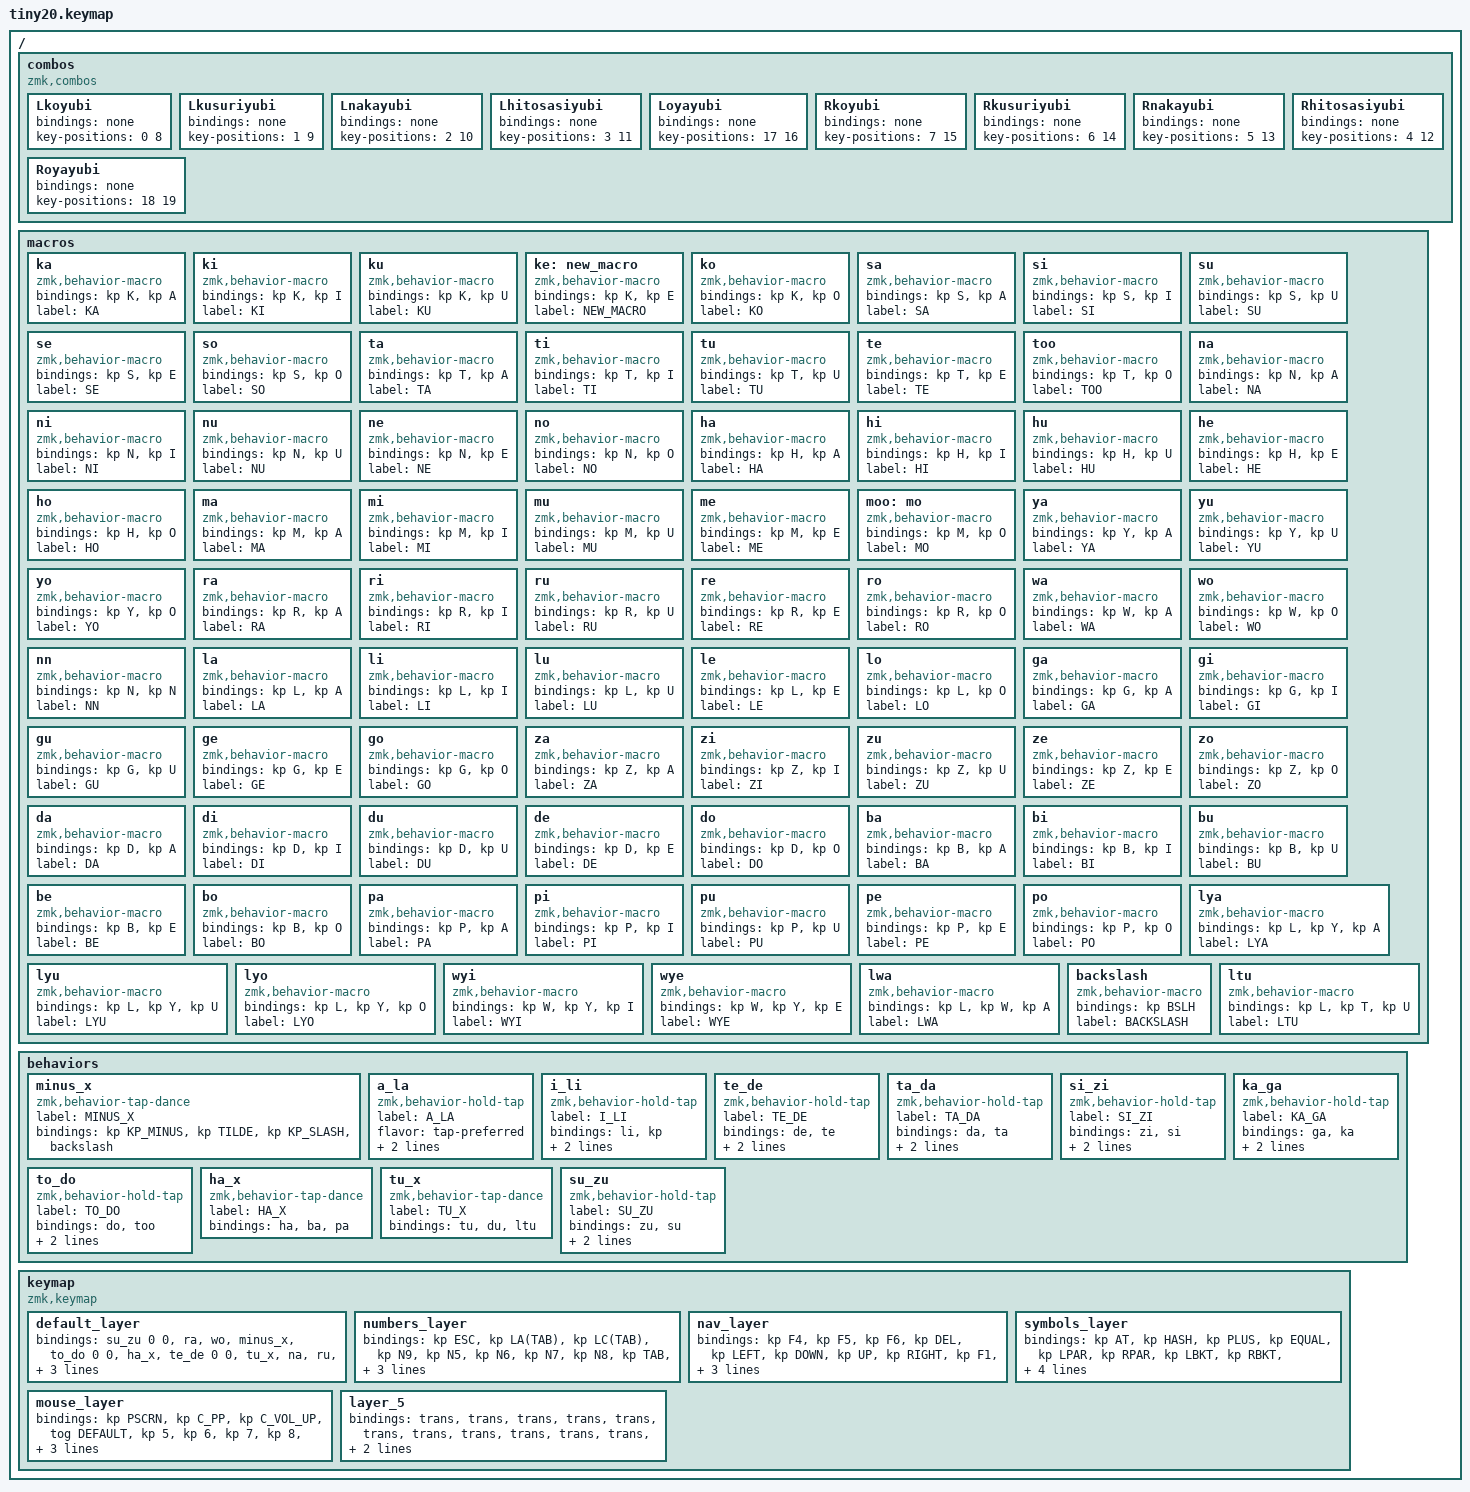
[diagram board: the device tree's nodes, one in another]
/*
 * Copyright (c) 2022 The ZMK Contributors
 *
 * SPDX-License-Identifier: MIT
 */

#include <behaviors.dtsi>
#include <dt-bindings/zmk/keys.h>

#define DEFAULT 0
#define NUMBERS 1
#define NAV 2
#define SYMBOLS 3
#define MOUSE 4

/ {
    combos {
        compatible = "zmk,combos";

        Lkoyubi {
            bindings = <&none>;
            key-positions = <0 8>;
        };

        Lkusuriyubi {
            bindings = <&none>;
            key-positions = <1 9>;
        };

        Lnakayubi {
            bindings = <&none>;
            key-positions = <2 10>;
        };

        Lhitosasiyubi {
            bindings = <&none>;
            key-positions = <3 11>;
        };

        Loyayubi {
            bindings = <&none>;
            key-positions = <17 16>;
        };

        Rkoyubi {
            bindings = <&none>;
            key-positions = <7 15>;
        };

        Rkusuriyubi {
            bindings = <&none>;
            key-positions = <6 14>;
        };

        Rnakayubi {
            bindings = <&none>;
            key-positions = <5 13>;
        };

        Rhitosasiyubi {
            bindings = <&none>;
            key-positions = <4 12>;
        };

        Royayubi {
            bindings = <&none>;
            key-positions = <18 19>;
        };
    };

    macros {
        ka: ka {
            compatible = "zmk,behavior-macro";
            #binding-cells = <0>;
            bindings = <&kp K &kp A>;
            label = "KA";
        };

        ki: ki {
            compatible = "zmk,behavior-macro";
            #binding-cells = <0>;
            bindings = <&kp K &kp I>;
            label = "KI";
        };

        ku: ku {
            compatible = "zmk,behavior-macro";
            #binding-cells = <0>;
            bindings = <&kp K &kp U>;
            label = "KU";
        };

        ke: new_macro {
            compatible = "zmk,behavior-macro";
            #binding-cells = <0>;
            bindings = <&kp K &kp E>;
            label = "NEW_MACRO";
        };

        ko: ko {
            compatible = "zmk,behavior-macro";
            #binding-cells = <0>;
            bindings = <&kp K &kp O>;
            label = "KO";
        };

        sa: sa {
            compatible = "zmk,behavior-macro";
            #binding-cells = <0>;
            bindings = <&kp S &kp A>;
            label = "SA";
        };

        si: si {
            compatible = "zmk,behavior-macro";
            #binding-cells = <0>;
            bindings = <&kp S &kp I>;
            label = "SI";
        };

        su: su {
            compatible = "zmk,behavior-macro";
            #binding-cells = <0>;
            bindings = <&kp S &kp U>;
            label = "SU";
        };

        se: se {
            compatible = "zmk,behavior-macro";
            #binding-cells = <0>;
            bindings = <&kp S &kp E>;
            label = "SE";
        };

        so: so {
            compatible = "zmk,behavior-macro";
            #binding-cells = <0>;
            bindings = <&kp S &kp O>;
            label = "SO";
        };

        ta: ta {
            compatible = "zmk,behavior-macro";
            #binding-cells = <0>;
            bindings = <&kp T &kp A>;
            label = "TA";
        };

        ti: ti {
            compatible = "zmk,behavior-macro";
            #binding-cells = <0>;
            bindings = <&kp T &kp I>;
            label = "TI";
        };

        tu: tu {
            compatible = "zmk,behavior-macro";
            #binding-cells = <0>;
            bindings = <&kp T &kp U>;
            label = "TU";
        };

        te: te {
            compatible = "zmk,behavior-macro";
            #binding-cells = <0>;
            bindings = <&kp T &kp E>;
            label = "TE";
        };

        too: too {
            compatible = "zmk,behavior-macro";
            #binding-cells = <0>;
            bindings = <&kp T &kp O>;
            label = "TOO";
        };

        na: na {
            compatible = "zmk,behavior-macro";
            #binding-cells = <0>;
            bindings = <&kp N &kp A>;
            label = "NA";
        };

        ni: ni {
            compatible = "zmk,behavior-macro";
            #binding-cells = <0>;
            bindings = <&kp N &kp I>;
            label = "NI";
        };

        nu: nu {
            compatible = "zmk,behavior-macro";
            #binding-cells = <0>;
            bindings = <&kp N &kp U>;
            label = "NU";
        };

        ne: ne {
            compatible = "zmk,behavior-macro";
            #binding-cells = <0>;
            bindings = <&kp N &kp E>;
            label = "NE";
        };

        no: no {
            compatible = "zmk,behavior-macro";
            #binding-cells = <0>;
            bindings = <&kp N &kp O>;
            label = "NO";
        };

        ha: ha {
            compatible = "zmk,behavior-macro";
            #binding-cells = <0>;
            bindings = <&kp H &kp A>;
            label = "HA";
        };

        hi: hi {
            compatible = "zmk,behavior-macro";
            #binding-cells = <0>;
            bindings = <&kp H &kp I>;
            label = "HI";
        };

        hu: hu {
            compatible = "zmk,behavior-macro";
            #binding-cells = <0>;
            bindings = <&kp H &kp U>;
            label = "HU";
        };

        he: he {
            compatible = "zmk,behavior-macro";
            #binding-cells = <0>;
            bindings = <&kp H &kp E>;
            label = "HE";
        };

        ho: ho {
            compatible = "zmk,behavior-macro";
            #binding-cells = <0>;
            bindings = <&kp H &kp O>;
            label = "HO";
        };

        ma: ma {
            compatible = "zmk,behavior-macro";
            #binding-cells = <0>;
            bindings = <&kp M &kp A>;
            label = "MA";
        };

        mi: mi {
            compatible = "zmk,behavior-macro";
            #binding-cells = <0>;
            bindings = <&kp M &kp I>;
            label = "MI";
        };

        mu: mu {
            compatible = "zmk,behavior-macro";
            #binding-cells = <0>;
            bindings = <&kp M &kp U>;
            label = "MU";
        };

        me: me {
            compatible = "zmk,behavior-macro";
            #binding-cells = <0>;
            bindings = <&kp M &kp E>;
            label = "ME";
        };

        moo: mo {
            compatible = "zmk,behavior-macro";
            #binding-cells = <0>;
            bindings = <&kp M &kp O>;
            label = "MO";
        };

        ya: ya {
            compatible = "zmk,behavior-macro";
            #binding-cells = <0>;
            bindings = <&kp Y &kp A>;
            label = "YA";
        };

        yu: yu {
            compatible = "zmk,behavior-macro";
            #binding-cells = <0>;
            bindings = <&kp Y &kp U>;
            label = "YU";
        };

        yo: yo {
            compatible = "zmk,behavior-macro";
            #binding-cells = <0>;
            bindings = <&kp Y &kp O>;
            label = "YO";
        };

        ra: ra {
            compatible = "zmk,behavior-macro";
            #binding-cells = <0>;
            bindings = <&kp R &kp A>;
            label = "RA";
        };

        ri: ri {
            compatible = "zmk,behavior-macro";
            #binding-cells = <0>;
            bindings = <&kp R &kp I>;
            label = "RI";
        };

        ru: ru {
            compatible = "zmk,behavior-macro";
            #binding-cells = <0>;
            bindings = <&kp R &kp U>;
            label = "RU";
        };

        re: re {
            compatible = "zmk,behavior-macro";
            #binding-cells = <0>;
            bindings = <&kp R &kp E>;
            label = "RE";
        };

        ro: ro {
            compatible = "zmk,behavior-macro";
            #binding-cells = <0>;
            bindings = <&kp R &kp O>;
            label = "RO";
        };

        wa: wa {
            compatible = "zmk,behavior-macro";
            #binding-cells = <0>;
            bindings = <&kp W &kp A>;
            label = "WA";
        };

        wo: wo {
            compatible = "zmk,behavior-macro";
            #binding-cells = <0>;
            bindings = <&kp W &kp O>;
            label = "WO";
        };

        nn: nn {
            compatible = "zmk,behavior-macro";
            #binding-cells = <0>;
            bindings = <&kp N &kp N>;
            label = "NN";
        };

        la: la {
            compatible = "zmk,behavior-macro";
            #binding-cells = <0>;
            bindings = <&kp L &kp A>;
            label = "LA";
        };

        li: li {
            compatible = "zmk,behavior-macro";
            #binding-cells = <0>;
            bindings = <&kp L &kp I>;
            label = "LI";
        };

        lu: lu {
            compatible = "zmk,behavior-macro";
            #binding-cells = <0>;
            bindings = <&kp L &kp U>;
            label = "LU";
        };

        le: le {
            compatible = "zmk,behavior-macro";
            #binding-cells = <0>;
            bindings = <&kp L &kp E>;
            label = "LE";
        };

        lo: lo {
            compatible = "zmk,behavior-macro";
            #binding-cells = <0>;
            bindings = <&kp L &kp O>;
            label = "LO";
        };

        ga: ga {
            compatible = "zmk,behavior-macro";
            #binding-cells = <0>;
            bindings = <&kp G &kp A>;
            label = "GA";
        };

        gi: gi {
            compatible = "zmk,behavior-macro";
            #binding-cells = <0>;
            bindings = <&kp G &kp I>;
            label = "GI";
        };

        gu: gu {
            compatible = "zmk,behavior-macro";
            #binding-cells = <0>;
            bindings = <&kp G &kp U>;
            label = "GU";
        };

        ge: ge {
            compatible = "zmk,behavior-macro";
            #binding-cells = <0>;
            bindings = <&kp G &kp E>;
            label = "GE";
        };

        go: go {
            compatible = "zmk,behavior-macro";
            #binding-cells = <0>;
            bindings = <&kp G &kp O>;
            label = "GO";
        };

        za: za {
            compatible = "zmk,behavior-macro";
            #binding-cells = <0>;
            bindings = <&kp Z &kp A>;
            label = "ZA";
        };

        zi: zi {
            compatible = "zmk,behavior-macro";
            #binding-cells = <0>;
            bindings = <&kp Z &kp I>;
            label = "ZI";
        };

        zu: zu {
            compatible = "zmk,behavior-macro";
            #binding-cells = <0>;
            bindings = <&kp Z &kp U>;
            label = "ZU";
        };

        ze: ze {
            compatible = "zmk,behavior-macro";
            #binding-cells = <0>;
            bindings = <&kp Z &kp E>;
            label = "ZE";
        };

        zo: zo {
            compatible = "zmk,behavior-macro";
            #binding-cells = <0>;
            bindings = <&kp Z &kp O>;
            label = "ZO";
        };

        da: da {
            compatible = "zmk,behavior-macro";
            #binding-cells = <0>;
            bindings = <&kp D &kp A>;
            label = "DA";
        };

        di: di {
            compatible = "zmk,behavior-macro";
            #binding-cells = <0>;
            bindings = <&kp D &kp I>;
            label = "DI";
        };

        du: du {
            compatible = "zmk,behavior-macro";
            #binding-cells = <0>;
            bindings = <&kp D &kp U>;
            label = "DU";
        };

        de: de {
            compatible = "zmk,behavior-macro";
            #binding-cells = <0>;
            bindings = <&kp D &kp E>;
            label = "DE";
        };

        do: do {
            compatible = "zmk,behavior-macro";
            #binding-cells = <0>;
            bindings = <&kp D &kp O>;
            label = "DO";
        };

        ba: ba {
            compatible = "zmk,behavior-macro";
            #binding-cells = <0>;
            bindings = <&kp B &kp A>;
            label = "BA";
        };

        bi: bi {
            compatible = "zmk,behavior-macro";
            #binding-cells = <0>;
            bindings = <&kp B &kp I>;
            label = "BI";
        };

        bu: bu {
            compatible = "zmk,behavior-macro";
            #binding-cells = <0>;
            bindings = <&kp B &kp U>;
            label = "BU";
        };

        be: be {
            compatible = "zmk,behavior-macro";
            #binding-cells = <0>;
            bindings = <&kp B &kp E>;
            label = "BE";
        };

        bo: bo {
            compatible = "zmk,behavior-macro";
            #binding-cells = <0>;
            bindings = <&kp B &kp O>;
            label = "BO";
        };

        pa: pa {
            compatible = "zmk,behavior-macro";
            #binding-cells = <0>;
            bindings = <&kp P &kp A>;
            label = "PA";
        };

        pi: pi {
            compatible = "zmk,behavior-macro";
            #binding-cells = <0>;
            bindings = <&kp P &kp I>;
            label = "PI";
        };

        pu: pu {
            compatible = "zmk,behavior-macro";
            #binding-cells = <0>;
            bindings = <&kp P &kp U>;
            label = "PU";
        };

        pe: pe {
            compatible = "zmk,behavior-macro";
            #binding-cells = <0>;
            bindings = <&kp P &kp E>;
            label = "PE";
        };

        po: po {
            compatible = "zmk,behavior-macro";
            #binding-cells = <0>;
            bindings = <&kp P &kp O>;
            label = "PO";
        };

        lya: lya {
            compatible = "zmk,behavior-macro";
            #binding-cells = <0>;
            bindings = <&kp L &kp Y &kp A>;
            label = "LYA";
        };

        lyu: lyu {
            compatible = "zmk,behavior-macro";
            #binding-cells = <0>;
            bindings = <&kp L &kp Y &kp U>;
            label = "LYU";
        };

        lyo: lyo {
            compatible = "zmk,behavior-macro";
            #binding-cells = <0>;
            bindings = <&kp L &kp Y &kp O>;
            label = "LYO";
        };

        wyi: wyi {
            compatible = "zmk,behavior-macro";
            #binding-cells = <0>;
            bindings = <&kp W &kp Y &kp I>;
            label = "WYI";
        };

        wye: wye {
            compatible = "zmk,behavior-macro";
            #binding-cells = <0>;
            bindings = <&kp W &kp Y &kp E>;
            label = "WYE";
        };

        lwa: lwa {
            compatible = "zmk,behavior-macro";
            #binding-cells = <0>;
            bindings = <&kp L &kp W &kp A>;
            label = "LWA";
        };

        backslash: backslash {
            compatible = "zmk,behavior-macro";
            #binding-cells = <0>;
            bindings = <&kp BSLH>;
            label = "BACKSLASH";
        };

        ltu: ltu {
            compatible = "zmk,behavior-macro";
            #binding-cells = <0>;
            bindings = <&kp L &kp T &kp U>;
            label = "LTU";
        };
    };

    behaviors {
        minus_x: minus_x {
            compatible = "zmk,behavior-tap-dance";
            label = "MINUS_X";
            #binding-cells = <0>;
            bindings =
                <&kp KP_MINUS>,
                <&kp TILDE>,
                <&kp KP_SLASH>,
                <&backslash>;
        };

        a_la: a_la {
            compatible = "zmk,behavior-hold-tap";
            label = "A_LA";
            #binding-cells = <2>;
            flavor = "tap-preferred";
            tapping-term-ms = <1>;
            bindings = <&la>, <&kp>;
        };

        i_li: i_li {
            compatible = "zmk,behavior-hold-tap";
            label = "I_LI";
            bindings = <&li>, <&kp>;

            #binding-cells = <2>;
            tapping-term-ms = <1>;
            flavor = "tap-preferred";
        };

        te_de: te_de {
            compatible = "zmk,behavior-hold-tap";
            label = "TE_DE";
            bindings = <&de>, <&te>;

            #binding-cells = <2>;
            tapping-term-ms = <1>;
            flavor = "tap-preferred";
        };

        ta_da: ta_da {
            compatible = "zmk,behavior-hold-tap";
            label = "TA_DA";
            bindings = <&da>, <&ta>;

            #binding-cells = <2>;
            tapping-term-ms = <1>;
            flavor = "tap-preferred";
        };

        si_zi: si_zi {
            compatible = "zmk,behavior-hold-tap";
            label = "SI_ZI";
            bindings = <&zi>, <&si>;

            #binding-cells = <2>;
            flavor = "tap-preferred";
            tapping-term-ms = <1>;
        };

        ka_ga: ka_ga {
            compatible = "zmk,behavior-hold-tap";
            label = "KA_GA";
            bindings = <&ga>, <&ka>;

            #binding-cells = <2>;
            tapping-term-ms = <1>;
            flavor = "tap-preferred";
        };

        to_do: to_do {
            compatible = "zmk,behavior-hold-tap";
            label = "TO_DO";
            bindings = <&do>, <&too>;

            #binding-cells = <2>;
            tapping-term-ms = <1>;
            flavor = "tap-preferred";
        };

        ha_x: ha_x {
            compatible = "zmk,behavior-tap-dance";
            label = "HA_X";
            #binding-cells = <0>;
            bindings = <&ha>, <&ba>, <&pa>;
        };

        tu_x: tu_x {
            compatible = "zmk,behavior-tap-dance";
            label = "TU_X";
            #binding-cells = <0>;
            bindings = <&tu>, <&du>, <&ltu>;
        };

        su_zu: su_zu {
            compatible = "zmk,behavior-hold-tap";
            label = "SU_ZU";
            bindings = <&zu>, <&su>;

            #binding-cells = <2>;
            flavor = "tap-preferred";
            tapping-term-ms = <1>;
        };
    };

    keymap {
        compatible = "zmk,keymap";

        // This is a sample keymap intended to be replaced with your own

        default_layer {
            bindings = <
&su_zu 0 0  &ra  &wo  &minus_x  &to_do 0 0  &ha_x  &te_de 0 0  &tu_x  &na  &ru  &ni  &no  &i_li 0 I  &ta_da 0 0  &si_zi 0 0  &ka_ga 0 0  &tog 5  &lt NUMBERS ENTER  &lt NAV SPACE  &kp KP_COMMA
            >;
        };

        numbers_layer {
            bindings = <
&kp ESC  &kp LA(TAB)  &kp LC(TAB)  &kp N9  &kp N5  &kp N6  &kp N7  &kp N8  &kp TAB  &kp LA(F4)  &kp LC(F4)  &kp N0  &kp N1  &kp N2  &kp N3  &kp N4  &kp LCTRL  &lt NUMBERS SPACE  &lt NAV ENTER  &kp LSHFT
            >;
        };

        nav_layer {
            bindings = <
&kp F4  &kp F5  &kp F6  &kp DEL  &kp LEFT  &kp DOWN  &kp UP  &kp RIGHT  &kp F1  &kp F2  &kp F3  &kp BSPC  &kp HOME  &kp PG_DN  &kp PG_UP  &kp END  &kp LCTRL  &lt NUMBERS SPACE  &lt NAV ENTER  &kp LSHFT
            >;
        };

        symbols_layer {
            bindings = <
&kp AT  &kp HASH  &kp PLUS  &kp EQUAL  &kp LPAR  &kp RPAR  &kp LBKT  &kp RBKT  &kp GRAVE  &kp EXCL  &kp MINUS  &kp UNDER  &kp COLON  &kp SEMI  &kp BSLH  &kp FSLH  &kp LCTRL  &lt NUMBERS SPACE  &lt NAV ENTER  &kp LSHFT
            >;
        };

        mouse_layer {
            bindings = <
&kp PSCRN  &kp C_PP  &kp C_VOL_UP  &tog DEFAULT  &kp 5  &kp 6  &kp 7  &kp 8  &kp C_PREV  &kp C_MUTE  &kp C_VOL_DN  &kp C_NEXT  &kp 1  &kp 2  &kp 3  &kp 4  &kp LCTRL  &lt NUMBERS SPACE  &lt NAV ENTER  &kp LSHFT
            >;
        };

        layer_5 {
            bindings = <
&trans  &trans  &trans  &trans  &trans  &trans  &trans  &trans  &trans  &trans  &trans  &trans  &trans  &trans  &trans  &trans  &trans  &trans  &trans  &trans
            >;
        };
    };
};
